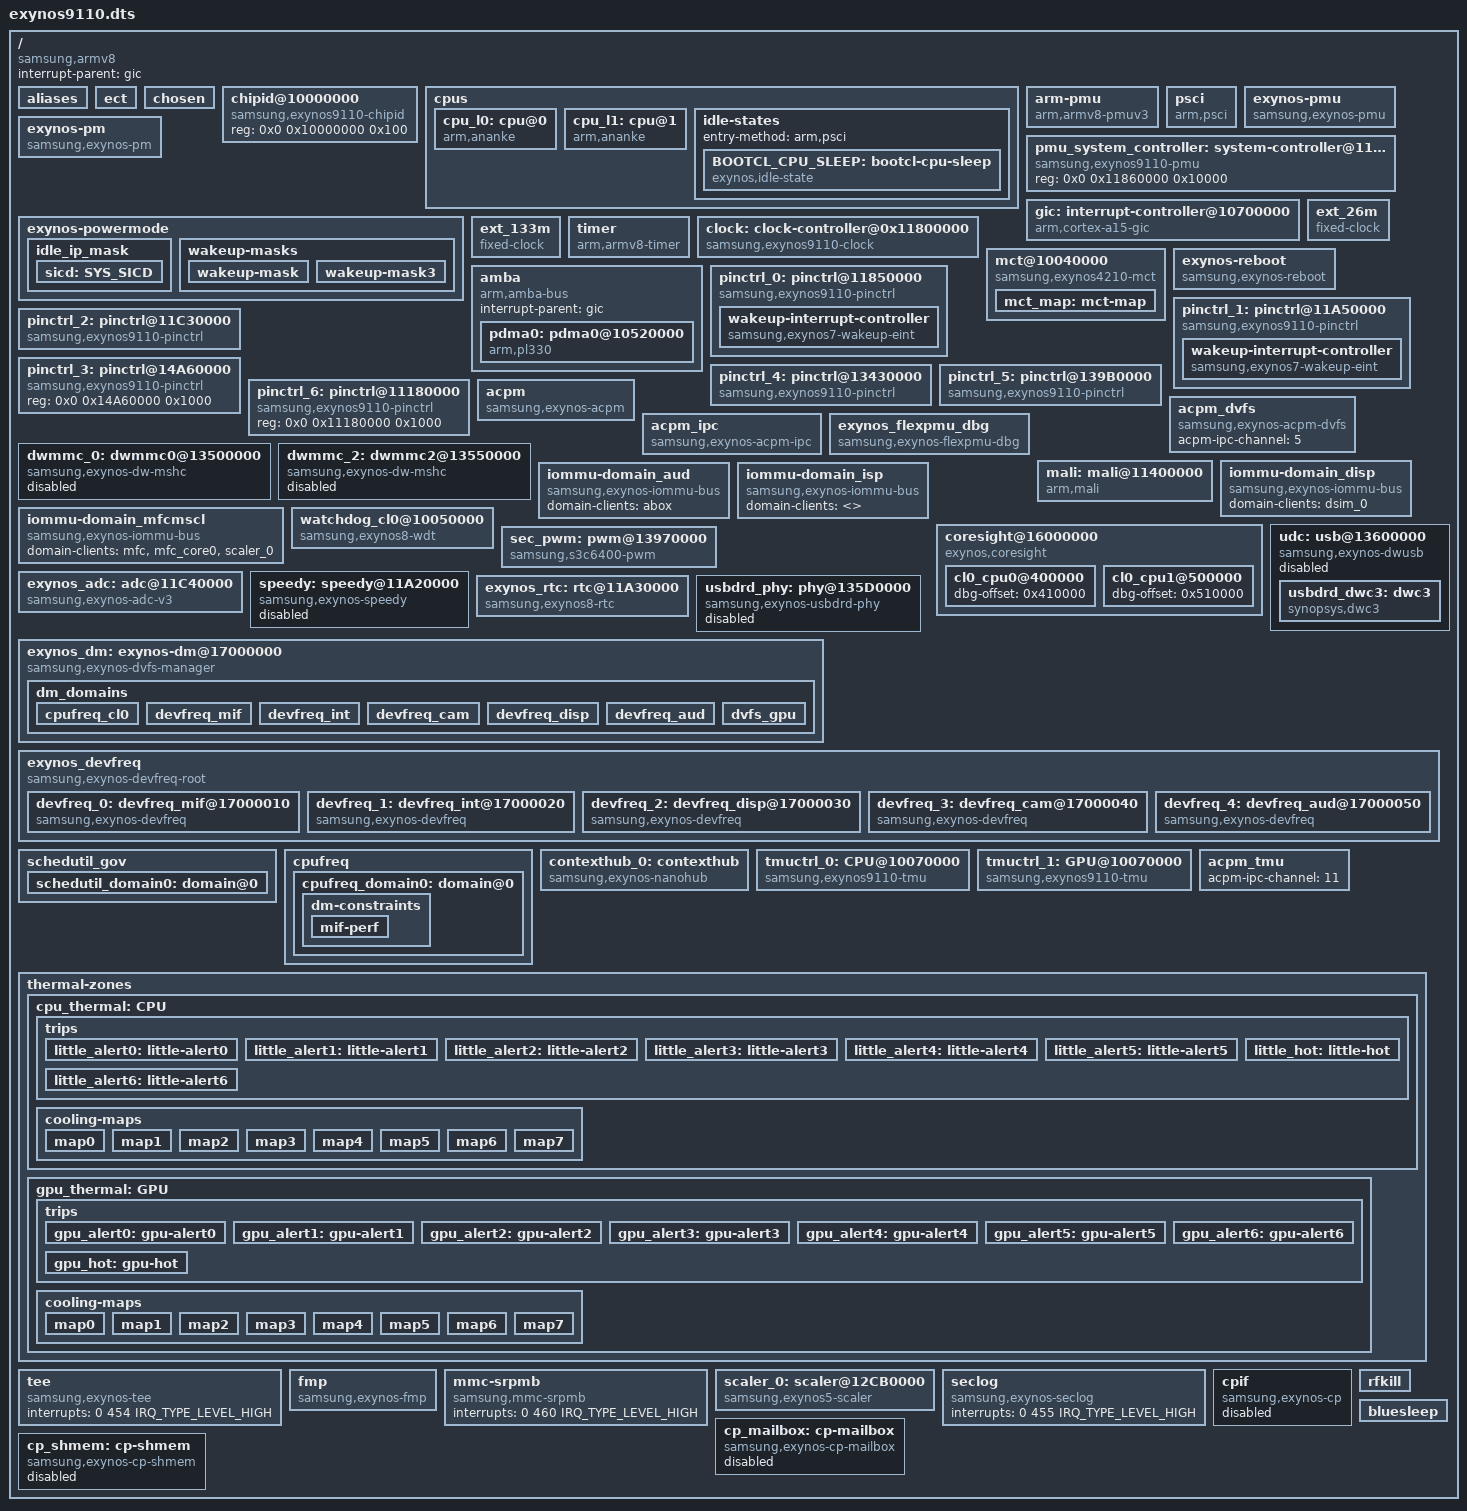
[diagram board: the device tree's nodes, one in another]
/*
 * SAMSUNG EXYNOS9110 SoC device tree source
 *
 * Copyright (c) 2017 Samsung Electronics Co., Ltd.
 *		http://www.samsung.com
 *
 * SAMSUNG EXYNOS9110 SoC device nodes are listed in this file.
 * EXYNOS9110 based board files can include this file and provide
 * values for board specfic bindings.
 *
 * This program is free software; you can redistribute it and/or modify
 * it under the terms of the GNU General Public License version 2 as
 * published by the Free Software Foundation.
 */
/dts-v1/;

#include "exynos9110-rmem.dtsi"
#include <dt-bindings/clock/exynos9110.h>
#include <dt-bindings/soc/samsung/exynos9110-dm.h>
#include <dt-bindings/soc/samsung/exynos9110-devfreq.h>
#include <dt-bindings/interrupt-controller/arm-gic.h>
#include <dt-bindings/interrupt-controller/exynos9110.h>
#include "exynos9110-dpu.dtsi"
#include "exynos9110-pinctrl.dtsi"
#include "exynos9110-usi.dtsi"
#include "exynos9110-sysmmu.dtsi"
#include "exynos9110-pm-domains.dtsi"
#include "exynos9110-audio.dtsi"
#include "exynos9110-debug.dtsi"
#include "exynos9110-mfc.dtsi"
#include "exynos9110-bts.dtsi"

/ {
	compatible = "samsung,armv8", "samsung,exynos9110";
	interrupt-parent = <&gic>;
	#address-cells = <2>;
	#size-cells = <1>;

	aliases {
		pinctrl0 = &pinctrl_0;
		pinctrl1 = &pinctrl_1;
		pinctrl2 = &pinctrl_2;
		pinctrl3 = &pinctrl_3;
		pinctrl4 = &pinctrl_4;
		pinctrl5 = &pinctrl_5;
		pinctrl6 = &pinctrl_6;
		mshc0 = &dwmmc_0;
		mshc2 = &dwmmc_2;
		scaler0 = &scaler_0;
		mfc0 = &mfc_core0;
		contexthub0 = &contexthub_0;
	};

	ect {
		parameter_address = <0x90000000>;
		parameter_size = <0x32000>;
	};

	chosen {
		//bootargs = "console=ram skip_initramfs rootwait ro init=/init androidboot.hardware=samsungexynos9110 androidboot.selinux=permissive androidboot.debug_level=0x4948 firmware_class.path=/vendor/firmware bcm_setup=0xffffff80f8e00000 ecd_setup=disable sec_debug.cp=3";
		bootargs = "console=ram root=/dev/ram0 clocksource=arch_sys_counter clk_ignore_unused of_devlink=0 androidboot.hardware=exynos9110 firmware_class.path=/vendor/firmware androidboot.debug_level=0x4948 androidboot.selinux=permissive";
		linux,initrd-start = <0x84000000>;
		linux,initrd-end = <0x841FFFFF>;
	};

	chipid@10000000 {
		compatible = "samsung,exynos9110-chipid";
		reg = <0x0 0x10000000 0x100>;
	};

	cpus {
		#address-cells = <2>;
		#size-cells = <0>;

		cpu_l0:cpu@0 {
			device_type = "cpu";
			compatible = "arm,ananke", "arm,armv8";
			reg = <0x0 0x0>;
			enable-method = "psci";
			cpu-idle-states = <&BOOTCL_CPU_SLEEP>;
		};
		cpu_l1:cpu@1 {
			device_type = "cpu";
			compatible = "arm,ananke", "arm,armv8";
			reg = <0x0 0x1>;
			enable-method = "psci";
			cpu-idle-states = <&BOOTCL_CPU_SLEEP>;
		};
		idle-states {
			entry-method = "arm,psci";

			BOOTCL_CPU_SLEEP: bootcl-cpu-sleep {
				idle-state-name = "c2";
				compatible = "exynos,idle-state";
				arm,psci-suspend-param = <0x0010000>;
				entry-latency-us = <35>;
				exit-latency-us = <90>;
				min-residency-us = <750>;
				status = "okay";
			};
		};
	};

	arm-pmu {
		compatible = "arm,armv8-pmuv3";
		interrupts = <GIC_SPI 152 IRQ_TYPE_LEVEL_HIGH>,
			      <GIC_SPI 153 IRQ_TYPE_LEVEL_HIGH>;
		interrupt-affinity = <&cpu_l0>, <&cpu_l1>;
	};

	psci {
		compatible = "arm,psci";
		method = "smc";
		cpu_suspend = <0xC4000001>;
		cpu_off = <0x84000002>;
		cpu_on = <0xC4000003>;
	};

	exynos-pmu {
		compatible = "samsung,exynos-pmu";
		samsung,syscon-phandle = <&pmu_system_controller>;
		reg = <0x0 0x11860000 0x10000>;
		reg-names = "pmu_alive";
	};

	pmu_system_controller: system-controller@11860000 {
		compatible = "samsung,exynos9110-pmu", "syscon";
		reg = <0x0 0x11860000 0x10000>;
	};

	exynos-pm {
		compatible = "samsung,exynos-pm";
		reg = <0x0 0x11850000 0x1000>,
		    <0x0 0x10701200 0x100>;
		reg-names = "gpio_alive_base",
				"gicd_ispendrn_base";
		num-eint = <13>;
		num-gic = <16>;
		suspend_mode_idx = <8>;		/* SYS_SLEEP */
		suspend_psci_idx = <133>;	/* PSCI_SYSTEM_SLEEP */
		cp_call_mode_idx = <10>;	/* SYS_SLEEP_AUD_ON */
		cp_call_psci_idx = <133>;	/* PSCI_SYSTEM_SLEEP */

		usbl2_suspend_available = <1>;	/* SYS_SLEEP_AUD_ON */
		usbl2_suspend_mode_idx = <12>;	/* SYS_SLEEP_AUD_ON */
		extra_wakeup_stat = <0x640>;
		wake_lock = <0>;                /* 1: held wake_lock */
	};

	exynos-powermode {
		cpd_residency = <3000>;
		cpd_enabled = <0>;
		sicd_residency = <3000>;
		sicd_enabled = <0>;

		idle-ip = "13970000.pwm",		/* [ 0] pwm		*/
			  "11c40000.adc",		/* [ 1] adc		*/
			  "11d00000.hsi2c",		/* [ 2] hsi2c_0		*/
			  "11d10000.hsi2c",		/* [ 3] hsi2c_1		*/
			  "11d20000.hsi2c",		/* [ 4] hsi2c_2		*/
			  "11d30000.hsi2c",		/* [ 5] hsi2c_3		*/
			  "11d40000.hsi2c",		/* [ 6] hsi2c_4		*/
			  "11d50000.hsi2c",		/* [ 7] hsi2c_5		*/
			  "11d60000.hsi2c",		/* [ 8] hsi2c_6		*/
			  "11d70000.hsi2c",		/* [ 9] hsi2c_7		*/
			  "138a0000.hsi2c",		/* [10] hsi2c_8		*/
			  "13900000.hsi2c",		/* [11] hsi2c_9		*/
			  "13910000.hsi2c",		/* [12] hsi2c_10	*/
			  "11d00000.spi",		/* [13] spi_0		*/
			  "11d20000.spi",		/* [14] spi_1		*/
			  "11d40000.spi",		/* [15] spi_2		*/
			  "11d60000.spi",		/* [16] spi_3		*/
			  "13940000.spi",		/* [17] spi_4		*/
			  "13900000.spi",		/* [18] spi_5		*/
			  "13500000.dwmmc0",		/* [19] dwmmc0		*/
			  "13550000.dwmmc2",		/* [20] dwmmc2		*/
			  "13600000.usb",		/* [21] usb		*/
			  "148e0000.dsim",		/* [22] dsim		*/
			  /* index for power-domain */
			  "pd-dispaud",			/* [23] pd-dispaud	*/
			  "pd-g3d",			/* [24] pd-g3d		*/
			  "pd-is",			/* [25] pd-is		*/
			  "pd-mfcmscl",			/* [26] pd-mfcmscl	*/
			  "pd-vts";			/* [27] pd-vts		*/

		fix-idle-ip = "acpm_dvfs";
		fix-idle-ip-index = <96>;

		idle_ip_mask {
			sicd: SYS_SICD {
				mode-index = <0>;
				ref-idle-ip = <0>,  <1>,  <2>,  <3>,  <4>,  <5>,  <6>,  <7>,  <8>,  <9>,
					     <10>, <11>, <12>, <13>, <14>, <15>, <16>, <17>, <18>, <19>,
					     <20>, <21>, <22>,       <24>,       <26>,       <96>;
			};
		};

		wakeup-masks {
			/*
			 * wakeup_mask configuration
			 *	        SICD          SICD_CPD      AFTR          STOP
			 *              LPD           LPA           ALPA          DSTOP
			 *              SLEEP         SLEEP_VTS_ON  SLEEP_AUD_ON  FAPO USB_L2
			 */
			wakeup-mask {
				mask = <0x400001E0>, <0x0>,        <0x0>,        <0x0>,
				       <0x0>,        <0x0>,        <0x0>,        <0x0>,
				       <0x500F7E7E>, <0x500F7E7E>, <0x500F7E7E>, <0x0>, <0xD00D7E7E>;
				reg-offset = <0x610>;
			};
			wakeup-mask3 {
				mask = <0x0>,	     <0x0>, 	   <0x0>, 	 <0x0>,
				       <0x0>,        <0x0>,        <0x0>,        <0x0>,
				       <0xFFFF00FF>, <0xFFFF00FF>, <0xFFFF00FF>, <0x0>, <0xFFFF00FF>;
				reg-offset = <0x618>;
			};
		};
	};

	gic:interrupt-controller@10700000 {
		compatible = "arm,cortex-a15-gic", "arm,cortex-a9-gic";
		#interrupt-cells = <3>;
		#address-cells = <0>;
		interrupt-controller;
		reg =	<0x0 0x10701000 0x1000>,
			<0x0 0x10702000 0x1000>,
			<0x0 0x10704000 0x2000>,
			<0x0 0x10706000 0x2000>;
		interrupts = <1 9 0xf04>;
	};

	ext_26m: ext_26m {
		compatible = "fixed-clock";
		#clock-cells = <0>;
		clock-frequency = <26000000>;
		clock-output-names = "ext-26m";
	};

	ext_133m: ext_133m {
		compatible = "fixed-clock";
		#clock-cells = <0>;
		clock-frequency = <133250000>;
		clock-output-names = "ext-133m";
	};

	timer {
		compatible = "arm,armv8-timer";
		interrupts = <GIC_PPI 13
				(GIC_CPU_MASK_SIMPLE(8) | IRQ_TYPE_LEVEL_LOW)>,
			     <GIC_PPI 14
				(GIC_CPU_MASK_SIMPLE(8) | IRQ_TYPE_LEVEL_LOW)>,
			     <GIC_PPI 11
				(GIC_CPU_MASK_SIMPLE(8) | IRQ_TYPE_LEVEL_LOW)>,
			     <GIC_PPI 10
				(GIC_CPU_MASK_SIMPLE(8) | IRQ_TYPE_LEVEL_LOW)>;
	        clock-frequency = <26000000>;
	};

	clock: clock-controller@0x11800000 {
		compatible = "samsung,exynos9110-clock";
		reg = <0x0 0x11800000 0x8000>;
		acpm-ipc-channel = <0>;
		#clock-cells = <1>;
	};

	mct@10040000 {
		compatible = "samsung,exynos4210-mct";
		reg = <0x0 0x10040000 0x800>;
		interrupt-controller;
		#interrupt-cells = <1>;
		interrupt-parent = <&mct_map>;
		interrupts =	<0>, <1>, <2>, <3>,
				<4>, <5>, <6>, <7>,
				<8>, <9>, <10>, <11>;
		clocks = <&clock OSCCLK>, <&clock GATE_MCT>;
		clock-names = "fin_pll", "mct";

		mct_map: mct-map {
			#interrupt-cells = <1>;
			#address-cells = <0>;
			#size-cells = <0>;
			interrupt-map = <0 &gic 0 233 IRQ_TYPE_LEVEL_HIGH>,
					<1 &gic 0 234 IRQ_TYPE_LEVEL_HIGH>,
					<2 &gic 0 235 IRQ_TYPE_LEVEL_HIGH>,
					<3 &gic 0 236 IRQ_TYPE_LEVEL_HIGH>,
					<4 &gic 0 237 IRQ_TYPE_LEVEL_HIGH>,
					<5 &gic 0 238 IRQ_TYPE_LEVEL_HIGH>,
					<6 &gic 0 239 IRQ_TYPE_LEVEL_HIGH>,
					<7 &gic 0 240 IRQ_TYPE_LEVEL_HIGH>,
					<8 &gic 0 241 IRQ_TYPE_LEVEL_HIGH>,
					<9 &gic 0 242 IRQ_TYPE_LEVEL_HIGH>,
					<10 &gic 0 243 IRQ_TYPE_LEVEL_HIGH>,
					<11 &gic 0 244 IRQ_TYPE_LEVEL_HIGH>;
		};
	};

	exynos-reboot {
		compatible = "samsung,exynos-reboot";
		samsung,syscon-phandle = <&pmu_system_controller>;
		shutdown-offset = <0x330C>;
		shutdown-trigger = <0x100>;
		reboot-offset = <0x400>;
		reboot-trigger = <0x1>;
		reboot-cmd-offset = <0x0810>;
	};

	/* DMA */
	amba {
		#address-cells = <2>;
		#size-cells = <1>;
		compatible = "arm,amba-bus";
		interrupt-parent = <&gic>;
		ranges;

		pdma0: pdma0@10520000 {
			compatible = "arm,pl330", "arm,primecell";
			reg = <0x0 0x10520000 0x1000>;
			interrupts = <0 19 IRQ_TYPE_LEVEL_HIGH>;
			clocks = <&clock GATE_PDMA_CORE>;
			clock-names = "apb_pclk";
			#dma-cells = <1>;
			#dma-channels = <4>;
			#dma-requests = <32>;
			#dma-multi-irq = <1>;
			dma-arwrapper = <0x10524400>,
					<0x10524420>,
					<0x10524440>,
					<0x10524460>;
			dma-awwrapper = <0x10524404>,
					<0x10524424>,
					<0x10524444>,
					<0x10524464>;
			dma-instwrapper = <0x10524480>;
			dma-mask-bit = <36>;
			coherent-mask-bit = <36>;
		};
	};

	/* ALIVE */
	pinctrl_0: pinctrl@11850000 {
		compatible = "samsung,exynos9110-pinctrl";
		reg = <0x0 0x11850000 0x1000>;
		interrupts = <0 74 IRQ_TYPE_LEVEL_HIGH>, <0 75 IRQ_TYPE_LEVEL_HIGH>,
				<0 76 IRQ_TYPE_LEVEL_HIGH>, <0 77 IRQ_TYPE_LEVEL_HIGH>,
				<0 78 IRQ_TYPE_LEVEL_HIGH>, <0 79 IRQ_TYPE_LEVEL_HIGH>,
				<0 80 IRQ_TYPE_LEVEL_HIGH>, <0 81 IRQ_TYPE_LEVEL_HIGH>,
				<0 82 IRQ_TYPE_LEVEL_HIGH>, <0 83 IRQ_TYPE_LEVEL_HIGH>,
				<0 84 IRQ_TYPE_LEVEL_HIGH>, <0 85 IRQ_TYPE_LEVEL_HIGH>,
				<0 86 IRQ_TYPE_LEVEL_HIGH>, <0 87 IRQ_TYPE_LEVEL_HIGH>;
		wakeup-interrupt-controller {
			compatible = "samsung,exynos7-wakeup-eint";
		};
	};

	/* CMGP_ALIVE */
	pinctrl_1: pinctrl@11A50000{
		compatible = "samsung,exynos9110-pinctrl";
		reg = <0x0 0x11A50000 0x1000>;
		interrupts = <0 122 IRQ_TYPE_LEVEL_HIGH>, <0 123 IRQ_TYPE_LEVEL_HIGH>,
				<0 124 IRQ_TYPE_LEVEL_HIGH>, <0 125 IRQ_TYPE_LEVEL_HIGH>,
				<0 142 IRQ_TYPE_LEVEL_HIGH>, <0 143 IRQ_TYPE_LEVEL_HIGH>,
				<0 144 IRQ_TYPE_LEVEL_HIGH>, <0 145 IRQ_TYPE_LEVEL_HIGH>,
				<0 146 IRQ_TYPE_LEVEL_HIGH>, <0 147 IRQ_TYPE_LEVEL_HIGH>;
		wakeup-interrupt-controller {
			compatible = "samsung,exynos7-wakeup-eint";
		};
	};

	/* CMGP */
	pinctrl_2: pinctrl@11C30000{
		compatible = "samsung,exynos9110-pinctrl";
		reg = <0x0 0x11C30000 0x1000>;
		interrupts = <0 126 IRQ_TYPE_LEVEL_HIGH>, <0 127 IRQ_TYPE_LEVEL_HIGH>,
				<0 128 IRQ_TYPE_LEVEL_HIGH>, <0 129 IRQ_TYPE_LEVEL_HIGH>,
				<0 130 IRQ_TYPE_LEVEL_HIGH>, <0 131 IRQ_TYPE_LEVEL_HIGH>,
				<0 132 IRQ_TYPE_LEVEL_HIGH>, <0 133 IRQ_TYPE_LEVEL_HIGH>,
				<0 134 IRQ_TYPE_LEVEL_HIGH>, <0 135 IRQ_TYPE_LEVEL_HIGH>,
				<0 136 IRQ_TYPE_LEVEL_HIGH>, <0 137 IRQ_TYPE_LEVEL_HIGH>,
				<0 138 IRQ_TYPE_LEVEL_HIGH>, <0 139 IRQ_TYPE_LEVEL_HIGH>,
				<0 140 IRQ_TYPE_LEVEL_HIGH>, <0 141 IRQ_TYPE_LEVEL_HIGH>;
	};

	/* DISPAUD */
	pinctrl_3: pinctrl@14A60000{
		compatible = "samsung,exynos9110-pinctrl";
		reg = <0x0 0x14A60000 0x1000>;
	};

	/* FSYS */
	pinctrl_4: pinctrl@13430000 {
		compatible = "samsung,exynos9110-pinctrl";
		reg = <0x0 0x13430000 0x1000>;
		interrupts = <0 180 IRQ_TYPE_LEVEL_HIGH>;
	};

	/* PERI */
	pinctrl_5: pinctrl@139B0000 {
		compatible = "samsung,exynos9110-pinctrl";
		reg = <0x0 0x139B0000 0x1000>;
		interrupts = <0 256 IRQ_TYPE_LEVEL_HIGH>;
	};

	/* VTS */
	pinctrl_6: pinctrl@11180000{
		compatible = "samsung,exynos9110-pinctrl";
		reg = <0x0 0x11180000 0x1000>;
	};

	acpm {
		compatible = "samsung,exynos-acpm";
		#address-cells = <2>;
		#size-cells = <1>;
		acpm-ipc-channel = <4>;
		fvmap_offset = <0x6000>;
		reg = <0x0 0x11830000 0x1000>;		/* TIMER_APM */
		reg-names = "timer_apm";
		peritimer-cnt = <0xFFFF>;
	};

	acpm_dvfs {
		compatible = "samsung,exynos-acpm-dvfs";
		acpm-ipc-channel = <5>;
	};

	acpm_ipc {
		compatible = "samsung,exynos-acpm-ipc";
		#address-cells = <2>;
		#size-cells = <1>;
		interrupts = <0 106 IRQ_TYPE_LEVEL_HIGH>;	/* AP2APM MAILBOX SPI NUM*/
		reg = <0x0 0x11900000 0x1000>,		/* AP2APM MAILBOX */
			<0x0 0x2039000 0x30000>;	/* APM SRAM */
		initdata-base = <0x6F00>;
		num-timestamps = <32>;
		debug-log-level = <0>;
		logging-period = <500>;
		dump-base = <0x203C000>;
		dump-size = <0x17000>;			/* 92KB */
	};

	exynos_flexpmu_dbg {
		compatible = "samsung,exynos-flexpmu-dbg";
		#address-cells = <2>;
		#size-cells = <1>;
		data-base = <0x204A000>;
		data-size = <0x400>;
		reg = <0x0 0x11a30000 0x1000>;
	};

	dwmmc_0: dwmmc0@13500000 {
		compatible = "samsung,exynos-dw-mshc";
		reg = <0x0 0x13500000 0x2000>,
			<0x0 0x13508000 0x200>;
		reg-names = "dw_mmc",
			"cmdq_mem";
		interrupts = <0 176 IRQ_TYPE_LEVEL_HIGH>;
		#address-cells = <1>;
		#size-cells = <0>;
		clocks = <&clock FSYS_MMC_EMBD>, <&clock GATE_MMC_EMBD>;
		clock-names = "ciu", "ciu_gate";
		status = "disabled";
		fmp-id = <0>;
		smu-id = <0>;
	};

	dwmmc_2: dwmmc2@13550000 {
		compatible = "samsung,exynos-dw-mshc";
		reg = <0x0 0x13550000 0x2000>;
		reg-names = "dw_mmc";
		interrupts = <0 177 IRQ_TYPE_LEVEL_HIGH>;
		#address-cells = <1>;
		#size-cells = <0>;
		clocks = <&clock FSYS_MMC_CARD>, <&clock GATE_MMC_CARD>;
		clock-names = "ciu", "ciu_gate";
		status = "disabled";
	 };

	mali: mali@11400000 {
		compatible = "arm,mali";
		reg = <0x0 0x11400000 0x5000>;
		interrupts = <0 70 IRQ_TYPE_LEVEL_HIGH>, <0 71 IRQ_TYPE_LEVEL_HIGH>, <0 69 IRQ_TYPE_LEVEL_HIGH>;
		interrupt-names = "JOB", "MMU", "GPU";
		g3d_cmu_cal_id = <ACPM_DVFS_G3D>;
		power-domains = <&pd_g3d>;
		#cooling-cells = <2>; /* min followed by max */
	};

	iommu-domain_disp {
		compatible = "samsung,exynos-iommu-bus";
		#address-cells = <2>;
		#size-cells = <1>;
		ranges;

		domain-clients = <&dsim_0>;
	};
	iommu-domain_aud {
		compatible = "samsung,exynos-iommu-bus";
		#address-cells = <2>;
		#size-cells = <1>;
		ranges;

		domain-clients = <&abox>;
	};
	iommu-domain_isp {
		compatible = "samsung,exynos-iommu-bus";
		#address-cells = <2>;
		#size-cells = <1>;
		ranges;

		domain-clients = <>;
	};
	iommu-domain_mfcmscl {
		compatible = "samsung,exynos-iommu-bus";
		#address-cells = <2>;
		#size-cells = <1>;
		ranges;

		domain-clients = <&mfc>, <&mfc_core0>, <&scaler_0>;
	};

	coresight@16000000 {
		compatible = "exynos,coresight";
		base = <0x16000000>;
		sj-offset = <0x6000>;

		cl0_cpu0@400000 {
			device_type = "cs";
			dbg-offset = <0x410000>;
		};
		cl0_cpu1@500000 {
			device_type = "cs";
			dbg-offset = <0x510000>;
		};
	};

	watchdog_cl0@10050000 {
		compatible = "samsung,exynos8-wdt";
		reg = <0x0 0x10050000 0x100>;
		interrupts = <0 INTREQ__WDT_CLUSTER0 IRQ_TYPE_LEVEL_HIGH>;
		clocks = <&clock OSCCLK>, <&clock GATE_WDT_CLUSTER0>;
		clock-names = "rate_watchdog", "gate_watchdog";
		timeout-sec = <30>;
		samsung,syscon-phandle = <&pmu_system_controller>;
		index = <0>; /* if little cluster then index is 0 */
	};

	sec_pwm: pwm@13970000 {
		compatible = "samsung,s3c6400-pwm";
		reg = <0x0 0x13970000 0x1000>;
		samsung,pwm-outputs = <0>, <1>, <2>, <3>, <4>;
		#pwm-cells = <3>;
		clocks = <&clock GATE_PWM_MOTOR>, <&clock OSCCLK>;
		clock-names = "pwm_pclk", "pwm_sclk";
		status = "ok";
	};

	exynos_adc: adc@11C40000 {
		compatible = "samsung,exynos-adc-v3";
		reg = <0x0 0x11C40000 0x100>;
		interrupts = <0 INTREQ__ADC_CMGP_S0 IRQ_TYPE_LEVEL_HIGH>;
		#io-channel-cells = <1>;
		io-channel-ranges;
		clocks = <&clock GATE_ADC_CMGP_S0>;
		clock-names = "gate_adcif";
	};

	speedy: speedy@11A20000 {
		compatible = "samsung,exynos-speedy";
		reg = <0x0 0x11A20000 0x2000>;
		interrupts = <0 98 IRQ_TYPE_LEVEL_HIGH>;
		#address-cells = <1>;
		#size-cells = <0>;
		pinctrl-names = "default";
		pinctrl-0 = <&speedy_bus>;
#if 0
		clocks = <&clock GATE_SPEEDY_BATCHER_WRAP_BATCHER_AP>;
		clock-names = "gate_speedy";
#endif
		status = "disabled";
	};

	exynos_rtc: rtc@11A30000 {
		compatible = "samsung,exynos8-rtc";
		reg = <0x0 0x11A30000 0x100>;
		interrupts = <0 INTREQ__RTC_ALARM_INT IRQ_TYPE_LEVEL_HIGH>, <0 INTREQ__RTC_TIC_INT_0 IRQ_TYPE_LEVEL_HIGH>;
	};

	udc: usb@13600000 {
		compatible = "samsung,exynos-dwusb";
		clocks = <&clock GATE_USB20DRD_TOP_LINK>, <&clock GATE_USB20DRD_TOP_20CTRL>, <&clock GATE_USB20DRD_TOP_REFCLK>;
		clock-names = "hsdrd", "hsctrl", "refclk";
		reg = <0x0 0x13600000 0x10000>;
		#address-cells = <2>;
		#size-cells = <1>;
		ranges;
		status = "disabled";

		usbdrd_dwc3: dwc3 {
			compatible = "synopsys,dwc3";
			reg = <0x0 0x13600000 0x10000>;
			interrupts = <0 181 IRQ_TYPE_LEVEL_HIGH>;
			//suspend_clk_freq = <66000000>;
			tx-fifo-resize = <0>;
			adj-sof-accuracy = <0>;
			is_not_vbus_pad = <1>;
			enable_sprs_transfer = <1>;
			qos_int_level = <100000 200000>;
			phys = <&usbdrd_phy 0>, <&usbdrd_phy 1>;
			phy-names = "usb2-phy", "usb3-phy";
			/* check susphy support */
			xhci_l2_support = <0>;
			/* support usb audio offloading: 1, if not: 0 */
			usb_audio_offloading = <0>;
			/* don't support USB L2 sleep */
			ldos = <0>;
			/*
			 * dis-u2-freeclk-exists-quirk, dis_u2_susphy_quirk are alternative.
			 * One of them should be selected
			 */
			snps,dis-u2-freeclk-exists-quirk;
			/* snps,dis_u2_susphy_quirk; */
		};
	};

	usbdrd_phy: phy@135D0000 {
		compatible = "samsung,exynos-usbdrd-phy";
		reg = <0x0 0x135D0000 0x200>;
		clocks = <&clock GATE_USB20DRD_TOP_LINK>, <&clock GATE_USB20DRD_TOP_20CTRL>, <&clock GATE_USB20DRD_TOP_REFCLK>,
			   <&clock OSCCLK>;
		clock-names = "hsdrd", "hsctrl", "refclk", "oscclk";
		samsung,pmu-syscon = <&pmu_system_controller>;
		pmu_mask = <0x1>;
		pmu_offset = <0x704>;
		//pmu_offset_dp = <0x66c>;

		/* USBDP combo phy version  - 0x200 */
		phy_version = <0x300>;
		/* if it doesn't need phy user mux, */
		/*  you should write "none" */
		/*  but refclk shouldn't be omitted */
		phyclk_mux = "none";
		phy_refclk = "oscclk";

		/* if Main phy has the other phy, it must be set to 1. jusf for usbphy_info */
		has_other_phy = <0>;
		/* if combo phy is used, it must be set to 1. usbphy_sub_info is enabled */
		has_combo_phy = <0>;
		sub_phy_version = <0x300>;

		/* ip type */
		/* USB3DRD = 0 */
		/*  USB3HOST = 1 */
		/*  USB2DRD = 2 */
		/*  USB2HOST = 3 */
		ip_type = <0x0>;

		/* for PHY CAL */
		/* choice only one item */
		phy_refsel_clockcore = <1>;
		phy_refsel_ext_osc = <0>;
		phy_refsel_xtal = <0>;
		phy_refsel_diff_pad = <0>;
		phy_refsel_diff_internal = <0>;
		phy_refsel_diff_single = <0>;

		/* true : 1 , false : 0 */
		use_io_for_ovc = <0>;
		common_block_disable = <1>;
		is_not_vbus_pad = <1>;
		used_phy_port = <0>;

		status = "disabled";

		#phy-cells = <1>;
		ranges;
	};

	exynos_dm: exynos-dm@17000000 {
		compatible = "samsung,exynos-dvfs-manager";
		reg = <0x0 0x17000000 0x0>;
		acpm-ipc-channel = <1>;
		dm_domains {
			cpufreq_cl0 {
				dm-index = <DM_CPU_CL0>;
				available = "true";
				cal_id = <ACPM_DVFS_CPUCL0>;
				dm_type_name = "dm_cpu_cl0";
			};
			devfreq_mif {
				dm-index = <DM_MIF>;
				available = "true";
				policy_use = "true";
				cal_id = <ACPM_DVFS_MIF>;
				dm_type_name = "dm_mif";
			};
			devfreq_int {
				dm-index = <DM_INT>;
				available = "true";
				policy_use = "true";
				cal_id = <ACPM_DVFS_INT>;
				dm_type_name = "dm_int";
			};
			devfreq_cam {
				dm-index = <DM_CAM>;
				available = "true";
				cal_id = <ACPM_DVFS_CAM>;
				dm_type_name = "dm_cam";
			};
			devfreq_disp {
				dm-index = <DM_DISP>;
				available = "true";
				cal_id = <ACPM_DVFS_DISP>;
				dm_type_name = "dm_disp";
			};
			devfreq_aud {
				dm-index = <DM_AUD>;
				available = "true";
				cal_id = <ACPM_DVFS_AUD>;
				dm_type_name = "dm_aud";
			};
			dvfs_gpu {
				dm-index = <DM_GPU>;
				available = "false";
				cal_id = <ACPM_DVFS_G3D>;
				dm_type_name = "dm_g3d";
			};
		};
	};

	exynos_devfreq {
		compatible = "samsung,exynos-devfreq-root";
		#address-cells = <2>;
		#size-cells = <1>;
		ranges;

		devfreq_0: devfreq_mif@17000010 {
			compatible = "samsung,exynos-devfreq";
			reg = <0x0 0x17000010 0x0>;
			devfreq_type = <DEVFREQ_MIF>;
			devfreq_domain_name = "dvfs_mif";
			pm_qos_class = <15>; /* PM_QOS_BUS_THROUGHPUT */
			pm_qos_class_max = <16>; /* PM_QOS_BUS_THROUGHPUT_MAX */
			ess_flag = <DSS_FLAG_MIF>;
			dm-index = <DM_MIF>;

			/* Delay time */
			use_delay_time = "false";

			freq_info = <1539000 421000 1014000 421000 1539000 1539000>;
			/* initial_freq, default_qos, suspend_freq, min_freq, max_freq reboot_freq */

			/* Booting value */
			boot_info = <40 1539000>;
			/* boot_qos_timeout, boot_freq */

			/* governor data */
			governor = <SIMPLE_INTERACTIVE>;

			bts_update = "false";
			dfs_id = <ACPM_DVFS_MIF>;
			acpm-ipc-channel = <1>;
			use_acpm = "true";
		};

		devfreq_1: devfreq_int@17000020 {
			compatible = "samsung,exynos-devfreq";
			reg = <0x0 0x17000020 0x0>;
			devfreq_type = <DEVFREQ_INT>;
			devfreq_domain_name = "dvfs_int";
			pm_qos_class = <11>; /* PM_QOS_DEVICE_THROUGHPUT */
			pm_qos_class_max = <13>; /* PM_QOS_DEVICE_THROUGHPUT_MAX */
			ess_flag = <DSS_FLAG_INT>;
			dm-index = <DM_INT>;

			/* Delay time */
			use_delay_time = "false";

			freq_info = <533000 100000 50000 100000 533000 533000>;
			/* <initial_freq, default_qos, suspend_freq, min, max, reboot_freq> */

			/* Booting value */
			boot_info = <40 533000>;
			/* boot_qos_timeout, boot_freq */

			/* governor data */
			governor = <SIMPLE_INTERACTIVE>;

			bts_update = "false";
			dfs_id = <ACPM_DVFS_INT>;
			acpm-ipc-channel = <1>;
			use_acpm = "true";
		};

		devfreq_2: devfreq_disp@17000030 {
			compatible = "samsung,exynos-devfreq";
			reg = <0x0 0x17000030 0x0>;
			devfreq_type = <DEVFREQ_DISP>;
			devfreq_domain_name = "dvfs_disp";
			pm_qos_class = <19>; /* PM_QOS_DISPLAY_THROUGHPUT */
			pm_qos_class_max = <20>; /* PM_QOS_DISPLAY_THROUGHPUT_MAX */
			ess_flag = <DSS_FLAG_DISP>;
			dm-index = <DM_DISP>;

			/* Delay time */
			use_delay_time = "false";

			freq_info = <178000 89000 890000 89000 178000 178000>;
			/* <initial_freq, default_qos, suspend_freq, min, max, reboot_freq> */

			/* Booting value */
			boot_info = <40 178000>;
			/* boot_qos_timeout, boot_freq */

			/* governor data */
			governor = <SIMPLE_INTERACTIVE>;
			pd_name = "pd-dispaud";

			bts_update = "false";
			dfs_id = <ACPM_DVFS_DISP>;
		};

		devfreq_3: devfreq_cam@17000040 {
			compatible = "samsung,exynos-devfreq";
			reg = <0x0 0x17000040 0x0>;
			devfreq_type = <DEVFREQ_CAM>;
			devfreq_domain_name = "dvfs_cam";
			pm_qos_class = <21>; /* PM_QOS_CAM_THROUGHPUT */
			pm_qos_class_max = <26>; /* PM_QOS_CAM_THROUGHPUT_MAX */
			ess_flag = <DSS_FLAG_ISP>;
			dm-index = <DM_CAM>;

			/* Delay time */
			use_delay_time = "false";

			freq_info = <50000 50000 50000 50000 334000 50000>;
			/* <initial, default_qos, suspend_freq, min, max, reboot_freq> */

			/* Booting value */
			boot_info = <40 50000>;
			/* boot_qos_timeout, boot_freq */

			/* governor data */
			governor = <SIMPLE_INTERACTIVE>;

			bts_update = "false";

			dfs_id = <ACPM_DVFS_CAM>;
		};

		devfreq_4: devfreq_aud@17000050 {
			compatible = "samsung,exynos-devfreq";
			reg = <0x0 0x17000050 0x0>;
			devfreq_type = <DEVFREQ_AUD>;
			devfreq_domain_name = "dvfs_aud";
			pm_qos_class = <22>; /* PM_QOS_AUD_THROUGHPUT */
			pm_qos_class_max = <27>; /* PM_QOS_AUD_THROUGHPUT_MAX */
			ess_flag = <DSS_FLAG_AUD>;
			dm-index = <DM_AUD>;

			/* Delay time */
			use_delay_time = "false";

			freq_info = <295000 295000 295000 295000 1180000 295000>;
			/* <initial, default_qos, suspend_freq, min, max, reboot_freq> */

			/* Booting value */
			boot_info = <40 295000>;
			/* boot_qos_timeout, boot_freq */

			/* governor data */
			governor = <SIMPLE_INTERACTIVE>;
			pd_name = "pd-dispaud";

			bts_update = "false";
			dfs_id = <ACPM_DVFS_AUD>;
		};
	};

	schedutil_gov {
		schedutil_domain0: domain@0 {
			device_type = "schedutil-domain";
			shared-cpus = "0-1";

			enabled = <0>;		/* Disable */
			qos_min_class = <3>;
		};
	};

	cpufreq {
		cpufreq_domain0: domain@0 {
			device_type = "cpufreq-domain";
			sibling-cpus = "0-1";
			cal-id = <ACPM_DVFS_CPUCL0>;
			dm-type = <DM_CPU_CL0>;

			/* PM QoS Class ID*/
			pm_qos-min-class = <3>;
			pm_qos-max-class = <4>;

			#cooling-cells = <2>; /* min followed by max */

			dm-constraints {
				mif-perf {
					const-type = <CONSTRAINT_MIN>;
					dm-type = <DM_MIF>;
						/*  cpu     mif  */
					table = < 1144000 845000
						  1099000 845000
						  1014000 845000
						   904000 676000
						   839000 676000
						   754000 676000
						   676000 421000
						   598000 421000
						   449000      0
						   299000      0
						   208000      0
						   >;
				};
			};

		 };
	};

	contexthub_0: contexthub {
		compatible = "samsung,exynos-nanohub";
		memory-region = <&chub_rmem>;
		/* INTREQ MAILBOX_AP2CHUB */
		interrupts = <0 110 IRQ_TYPE_LEVEL_HIGH>;
		/* mailbox, sram, dumpgpr, chub reset & chub cpu reset, osc rco, rtc cotrol */
		/* chub control, chub reset status, baaw_p_apm_shub */
		reg = <0x0 0x11A00000 0x200>,
		    <0x0 0x10E00000 0xC0000>,
		    <0x0 0x10CF0000 0x100>,
		    <0x0 0x11868900 0x10>,
		    <0x0 0x11860b1c 0x10>,
		    <0x0 0x1186073c 0x10>,
		    <0x0 0x1186007c 0x10>,
		    <0x0 0x11860504 0x10>,
		    <0x0 0x10D20000 0x20>;
		reg-names = "mailbox", "sram", "dumpgpr", "chub_reset",
			"osc_rco", "rtc_ctrl", "chub_ctrl", "chub_reset_status",
			"chub_baaw_p_apm";
		/* BAAW-P-APM-SHUB */
		baaw,baaw-p-apm-chub = <0x40300 0x40800 0x11900 0x80000003>;
		/* none, pass, os.checked.bin, Exynos9610.bin */
		os-type = "os.checked.bin";
	};

	tmuctrl_0: CPU@10070000 {
		compatible = "samsung,exynos9110-tmu";
		reg = <0x0 0x10070000 0x700>;
		interrupts = <0 INTREQ__TMU IRQ_TYPE_LEVEL_HIGH>;
		tmu_name = "CPU";
		id = <0>;
		sensors = <1>;		/* 0x1 */
		sensing_mode = "max";
		#include "exynos9110-tmu-sensor-conf.dtsi"
	};

	tmuctrl_1: GPU@10070000 {
		compatible = "samsung,exynos9110-tmu";
		reg = <0x0 0x10070000 0x700>;
		interrupts = <0 INTREQ__TMU IRQ_TYPE_LEVEL_HIGH>;
		tmu_name = "GPU";
		id = <1>;
		sensors = <1>;		/* 0x1 */
		sensing_mode = "max";
		#include "exynos9110-tmu-sensor-conf.dtsi"
	};

	acpm_tmu {
		acpm-ipc-channel = <11>;
	};

	thermal-zones {
		cpu_thermal: CPU {
			zone_name  = "CPU_THERMAL";
			polling-delay-passive = <0>;
			polling-delay = <0>;
			thermal-sensors = <&tmuctrl_0>;

			trips {
				little_alert0: little-alert0 {
					temperature = <20000>; /* millicelsius */
					hysteresis = <5000>; /* millicelsius */
					type = "active";
				};
				little_alert1: little-alert1 {
					temperature = <76000>; /* millicelsius */
					hysteresis = <5000>; /* millicelsius */
					type = "active";
				};
				little_alert2: little-alert2 {
					temperature = <81000>; /* millicelsius */
					hysteresis = <5000>; /* millicelsius */
					type = "active";
				};
				little_alert3: little-alert3 {
					temperature = <86000>; /* millicelsius */
					hysteresis = <5000>; /* millicelsius */
					type = "active";
				};
				little_alert4: little-alert4 {
					temperature = <91000>; /* millicelsius */
					hysteresis = <5000>; /* millicelsius */
					type = "active";
				};
				little_alert5: little-alert5 {
					temperature = <96000>; /* millicelsius */
					hysteresis = <5000>; /* millicelsius */
					type = "active";
				};
				little_alert6: little-alert6 {
					temperature = <101000>; /* millicelsius */
					hysteresis = <5000>; /* millicelsius */
					type = "active";
				};
				little_hot: little-hot {
					temperature = <115000>; /* millicelsius */
					hysteresis = <5000>; /* millicelsius */
					type = "hot";
				};
			};

			cooling-maps {
				map0 {
				     trip = <&little_alert0>;
				     /* Corresponds to 1099MHz at freq_table */
				     cooling-device = <&cpufreq_domain0 0 0>;
				};
				map1 {
				     trip = <&little_alert1>;
				     /* Corresponds to 1014MHz at freq_table */
				     cooling-device = <&cpufreq_domain0 0 0>;
			       };
				map2 {
				     trip = <&little_alert2>;
				     /* Corresponds to 904MHz at freq_table */
				     cooling-device = <&cpufreq_domain0 0 0>;
				};
				map3 {
				     trip = <&little_alert3>;
				     /* Corresponds to 839MHz at freq_table */
				     cooling-device = <&cpufreq_domain0 0 0>;
				};
				map4 {
				     trip = <&little_alert4>;
				     /* Corresponds to 754MHz at freq_table */
				     cooling-device = <&cpufreq_domain0 0 0>;
				};
				map5 {
				     trip = <&little_alert5>;
				     /* Corresponds to 676MHz at freq_table */
				     cooling-device = <&cpufreq_domain0 0 0>;
			       };
				map6 {
				     trip = <&little_alert6>;
				     /* Corresponds to 598MHz at freq_table */
				     cooling-device = <&cpufreq_domain0 0 0>;
				};
				map7 {
				     trip = <&little_hot>;
				     /* Corresponds to 449MHz at freq_table */
				     cooling-device = <&cpufreq_domain0 0 0>;
				};
			};
		};

		gpu_thermal: GPU {
			zone_name  = "GPU_THERMAL";
			polling-delay-passive = <0>;
			polling-delay = <0>;
			thermal-sensors = <&tmuctrl_1>;

			trips {
				gpu_alert0: gpu-alert0 {
					temperature = <20000>; /* millicelsius */
					hysteresis = <5000>; /* millicelsius */
					type = "active";
				};
				gpu_alert1: gpu-alert1 {
					temperature = <76000>; /* millicelsius */
					hysteresis = <5000>; /* millicelsius */
					type = "active";
				};
				gpu_alert2: gpu-alert2 {
					temperature = <81000>; /* millicelsius */
					hysteresis = <5000>; /* millicelsius */
					type = "active";
				};
				gpu_alert3: gpu-alert3 {
					temperature = <86000>; /* millicelsius */
					hysteresis = <5000>; /* millicelsius */
					type = "active";
				};
				gpu_alert4: gpu-alert4 {
					temperature = <91000>; /* millicelsius */
					hysteresis = <5000>; /* millicelsius */
					type = "active";
				};
				gpu_alert5: gpu-alert5 {
					temperature = <96000>; /* millicelsius */
					hysteresis = <5000>; /* millicelsius */
					type = "active";
				};
				gpu_alert6: gpu-alert6 {
					temperature = <101000>; /* millicelsius */
					hysteresis = <5000>; /* millicelsius */
					type = "active";
				};
				gpu_hot: gpu-hot {
					temperature = <115000>; /* millicelsius */
					hysteresis = <5000>; /* millicelsius */
					type = "hot";
				};
			};

			cooling-maps {
				map0 {
				     trip = <&gpu_alert0>;
				     cooling-device = <&mali 0 0>;
				};
				map1 {
				     trip = <&gpu_alert1>;
				     cooling-device = <&mali 0 0>;
			       };
				map2 {
				     trip = <&gpu_alert2>;
				     cooling-device = <&mali 0 0>;
				};
				map3 {
				     trip = <&gpu_alert3>;
				     cooling-device = <&mali 0 0>;
				};
				map4 {
				     trip = <&gpu_alert4>;
				     cooling-device = <&mali 0 0>;
				};
				map5 {
				     trip = <&gpu_alert5>;
				     cooling-device = <&mali 0 0>;
			       };
				map6 {
				     trip = <&gpu_alert6>;
				     cooling-device = <&mali 0 0>;
				};
				map7 {
				     trip = <&gpu_hot>;
				     cooling-device = <&mali 0 0>;
				};
			};
		};
	};

	/* tbase */
	tee {
		compatible = "samsung,exynos-tee";
	        interrupts = <0 454 IRQ_TYPE_LEVEL_HIGH>;
	};

	fmp: fmp {
		compatible = "samsung,exynos-fmp";
		exynos,block-type = "mmcblk0p";
		exynos,fips-block_offset = <5>;
	};

	mmc-srpmb {
		compatible = "samsung,mmc-srpmb";
		interrupts = <0 460 IRQ_TYPE_LEVEL_HIGH>;
	};

	scaler_0: scaler@12CB0000 {
		compatible = "samsung,exynos5-scaler";
		reg = <0x0 0x12CB0000 0x1300>;
		interrupts = <0 205 IRQ_TYPE_LEVEL_HIGH>;
		clocks = <&clock GATE_M2M>;
		clock-names = "gate";
		iommus = <&sysmmu_mfcmscl>;
		samsung,power-domain = <&pd_mfcmscl>;
	};

	/* Secure log */
	seclog {
		compatible = "samsung,exynos-seclog";
		interrupts = <0 455 IRQ_TYPE_LEVEL_HIGH>;
	};


	/* Modem interface information */
	cpif: cpif {
		compatible = "samsung,exynos-cp";
		interrupt-parent = <&gic>;
		interrupts = <GIC_SPI 300 IRQ_TYPE_LEVEL_HIGH>; /* INTREQ__MODEM_RESET */
		interrupt-names = "RESET_REQ";
		status = "disabled";
	};

	/* Mailbox information */
	cp_mailbox: cp-mailbox {
		compatible = "samsung,exynos-cp-mailbox";
		reg = <0x0 0x11920000 0x180>;
		interrupt-parent = <&gic>;
		interrupts = <GIC_SPI 107 IRQ_TYPE_LEVEL_HIGH>; /* INTREQ__MAILBOX_CP2AP */
		status = "disabled";
	};

	/* Shared memory information*/
	cp_shmem: cp-shmem {
		compatible = "samsung,exynos-cp-shmem";
		status = "disabled";
	};

	/* TODO (mullerf): b/159257766 */
	rfkill: rfkill {
	};
	bluesleep: bluesleep {
	};
};
